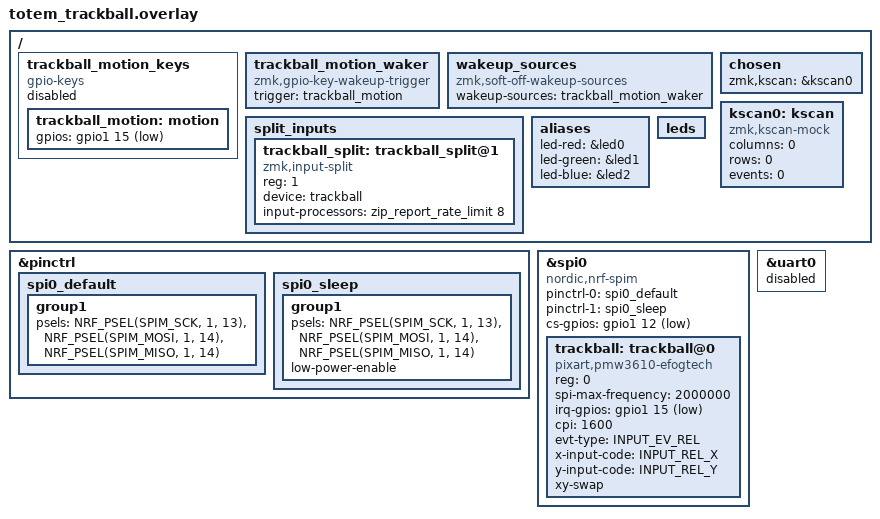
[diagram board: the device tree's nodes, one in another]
// ============================================================================
// ZMK Configuration for Ploopy Adept BLE Trackball
// Device Tree Overlay for XIAO BLE with PMW3610 Trackball Sensor
// ============================================================================

// ----------------------------------------------------------------------------
// Includes and Definitions
// ----------------------------------------------------------------------------

// #include <input/processors.dtsi>
#include <input/processors/report_rate_limit.dtsi>
// #include <dt-bindings/zmk/input_transform.h>
// #include <behaviors/input_gestures_accel.dtsi>

// #include "totem.dtsi"
#include <zephyr/dt-bindings/input/input-event-codes.h>

// ----------------------------------------------------------------------------
// Hardware Configuration: SPI Interface
// ----------------------------------------------------------------------------

&pinctrl {
    spi0_default: spi0_default {
        group1 {
            psels = <NRF_PSEL(SPIM_SCK,  1, 13)>, // SCLK P1.13 (Yellow wire)
                    <NRF_PSEL(SPIM_MOSI, 1, 14)>, // SDIO P1.14 (Orange wire)
                    <NRF_PSEL(SPIM_MISO, 1, 14)>; // SDIO P1.14 (shared MOSI/MISO)
        };
    };

    spi0_sleep: spi0_sleep {
        group1 {
            psels = <NRF_PSEL(SPIM_SCK,  1, 13)>, // SCLK P1.13
                    <NRF_PSEL(SPIM_MOSI, 1, 14)>, // SDIO P1.14
                    <NRF_PSEL(SPIM_MISO, 1, 14)>; // SDIO P1.14
            low-power-enable;
        };
    };
};

&spi0 {
    status = "okay";
    compatible = "nordic,nrf-spim";
    pinctrl-0 = <&spi0_default>;
    pinctrl-1 = <&spi0_sleep>;
    pinctrl-names = "default", "sleep";
    cs-gpios = <&gpio1 12 GPIO_ACTIVE_LOW>; // NCS P1.12 (Violet wire)

    // PMW3610 Trackball Sensor Configuration
    trackball: trackball@0 {
        status = "okay";
        compatible = "pixart,pmw3610-efogtech";
        reg = <0>;
        spi-max-frequency = <2000000>;  // 2MHz SPI clock
        irq-gpios = <&gpio1 15 (GPIO_ACTIVE_LOW | GPIO_PULL_UP)>; // MOT P1.15 (Brown wire)
        cpi = <1600>;                   // 1600 counts per inch - real resolution for
                                        // the 3840x2160 27" panel (163 PPI, unscaled
                                        // pointer space). Driver allows 200-3200 in
                                        // steps of 200. NOTE: sensor-dpi in the dongle
                                        // overlay must stay at 800 - see comment there.
        evt-type = <INPUT_EV_REL>;
        x-input-code = <INPUT_REL_X>;
        y-input-code = <INPUT_REL_Y>;
        xy-swap;                      // Maintain XY swapping without processor

        // No force-high-performance here: pmw3610_set_performance() wraps its whole
        // body in `if (config->force_awake)`, so without force-awake the property is
        // never read. It was dead config, implying a power mode that was not set.
        // force-awake itself stays off - it causes cursor warping on wake.
        // The sensor therefore runs its normal REST ladder, configured in the .conf.
    };
};

// ----------------------------------------------------------------------------
// Deep sleep wakeup source
// ----------------------------------------------------------------------------

/* The PMW3610 MOT line is what brings this part back from deep sleep.
 *
 * activity.c calls sys_poweroff(), and the only ways out of nRF52 System OFF are
 * the reset button or DETECT from a pin whose PIN_CNF SENSE is set. The pmw3610
 * driver does arm MOT as GPIO_INT_LEVEL_ACTIVE (pmw3610.c:290) during normal
 * operation, and gpio_nrfx routes a *level* trigger to SENSE rather than to a
 * GPIOTE channel - that branch is edge-only (gpio_nrfx.c:371-383) - but that
 * arming happens long before power-off and does not survive it. Only the reset
 * button woke this part.
 *
 * So MOT is declared here as a proper waker instead. zmk_pm_arm_wakeup_sources()
 * resumes it as the very last step before sys_poweroff(), which re-runs
 * gpio_pin_interrupt_configure_dt(GPIO_INT_LEVEL_ACTIVE) on the pin and so
 * re-sets SENSE with nothing left to clobber it. Rolling the ball pulls MOT low,
 * DETECT fires, and the nRF boots.
 *
 * Waking is a reset, not a resume, so the flick that wakes it is still spent on
 * the cold boot and the re-link to the dongle. That is inherent to System OFF.
 *
 * The gpio-keys node is deliberately `disabled`. It exists only to give the
 * waker a node with a `gpios` property to point at - GPIO_DT_SPEC_GET reads that
 * whatever the status. Left enabled, CONFIG_INPUT_GPIO_KEYS would default to y
 * (it is `default y` on DT_HAS_GPIO_KEYS_ENABLED, and CONFIG_INPUT=y here) and
 * Zephyr's input_gpio_keys driver would bind the node and configure P1.15 for
 * itself with an *edge* interrupt - which on nRF takes a GPIOTE channel and
 * clears the SENSE bit this whole node exists to set, breaking both the wake and
 * the sensor's own motion interrupt.
 */
/ {
    trackball_motion_keys {
        compatible = "gpio-keys";
        status = "disabled";

        trackball_motion: motion {
            // Same pin and flags as the sensor's irq-gpios: MOT on P1.15,
            // active low with a pull-up.
            gpios = <&gpio1 15 (GPIO_ACTIVE_LOW | GPIO_PULL_UP)>;
        };
    };

    trackball_motion_waker: trackball_motion_waker {
        compatible = "zmk,gpio-key-wakeup-trigger";
        trigger = <&trackball_motion>;
    };

    wakeup_sources {
        compatible = "zmk,soft-off-wakeup-sources";
        wakeup-sources = <&trackball_motion_waker>;
    };
};

/ {
    split_inputs {
        #address-cells = <1>;
        #size-cells = <0>;
        
        trackball_split: trackball_split@1 {
            compatible = "zmk,input-split";
            reg = <1>;  // Unique ID for the trackball
            device = <&trackball>;

            // Cap reports at 125 Hz (8ms) before they hit the BLE link to the
            // dongle. X/Y deltas are accumulated, not dropped, so no motion is
            // lost - unlike the queue overflow you get when the sensor reports
            // faster than the connection interval allows.
            input-processors = <&zip_report_rate_limit 8>;
        };
    };
};

// ----------------------------------------------------------------------------
// Pointer Acceleration Configuration
// ----------------------------------------------------------------------------

// &pointer_accel {
//     // This processor must be defined BEFORE the input-listener
//     input-type = <INPUT_EV_REL>;
//     codes = <INPUT_REL_X INPUT_REL_Y>;
//     
//     // Sensitivity and Acceleration Settings
//     sensitivity = <800>;              // 0.8x base sensitivity
// 	min-factor = <800>;		  // 0.8x minimum for percision
//     max-factor = <3000>;             // 3.0x maximum acceleration
//     acceleration-exponent = <1>;     // Advanced exponential curve (1-5)
//     
//     // Axis-Specific Settings
//     y-boost = <1000>;                // 1.0x Y-axis boost for widescreen monitors
//     
//     // Speed-Based Acceleration
//     speed-threshold = <900>;         // Start acceleration at 900 counts/sec (~1.5 inch/sec)
//     speed-max = <1800>;              // Max acceleration at 1800 counts/sec (~3 inch/sec)
//     
//     // Sensor Characteristics
//     sensor-dpi = <600>;              // Match sensor CPI setting
// };

// ----------------------------------------------------------------------------
// Input System Configuration
// ----------------------------------------------------------------------------

/ {
    chosen {
        // Mock keyboard scanner (no physical keys)
        zmk,kscan = &kscan0;
    };

    // Mock Keyboard Scanner Configuration
    kscan0: kscan {
        compatible = "zmk,kscan-mock";
        columns = <0>;
        rows = <0>;
        events = <0>;
    };

    // Trackball Input Listener
    // trackball_listener {
    //     compatible = "zmk,input-listener";
    //     device = <&trackball>;
        
    //     // Input Processing Pipeline
    //     // input-processors =
    //     //     <&pointer_accel>,                          // Apply pointer acceleration
    //     //     <&zip_ble_report_rate_limit 4>,           // Limit report rate to 4ms (250Hz)
    //     //     <&zip_xy_transform (INPUT_TRANSFORM_XY_SWAP)>; // Swap X and Y axes
    // };
};

// ----------------------------------------------------------------------------
// Peripheral Configuration
// ----------------------------------------------------------------------------

// Disable UART to avoid pin conflicts with SPI interface
&uart0 {
    status = "disabled";
};

/ {
    aliases {
        led-red = &led0;
        led-green = &led1;
        led-blue = &led2;
    };

    leds {
        status = "okay";
    };
};

// ============================================================================
// End of Configuration
// ============================================================================

/* More about input processors: https://zmk.dev/docs/keymaps/input-processors#input-processors-overview */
